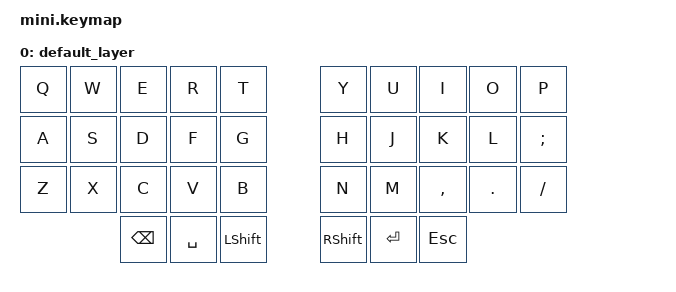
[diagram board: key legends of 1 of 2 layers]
#include <behaviors.dtsi>
#include <dt-bindings/zmk/keys.h>

/ {
    keymap {
        compatible = "zmk,keymap";
        default_layer { // Layer 0
            bindings = <
                &kp Q  &kp W  &kp E  &kp R  &kp T   &kp Y  &kp U  &kp I     &kp O     &kp P
                &kp A  &kp S  &kp D  &kp F  &kp G   &kp H  &kp J  &kp K     &kp L     &kp SCLN
                &kp Z  &kp X  &kp C  &kp V  &kp B   &kp N  &kp M  &kp COMMA &kp DOT  &kp FSLH
                      &kp BSPC  &kp SPACE  &kp LSHFT   &kp RSHFT  &kp RET  &kp ESC
            >;
        };
        upper_layer { // Layer 1
            bindings = <

            >;
        };
    };
};
